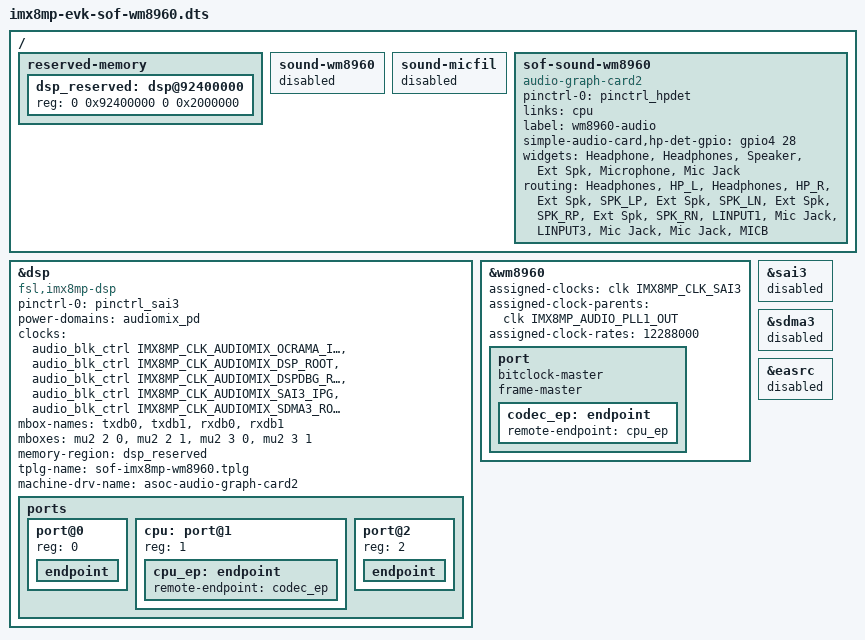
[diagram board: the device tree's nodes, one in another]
// SPDX-License-Identifier: GPL-2.0+
// Copyright NXP 2020

#include "imx8mp-evk.dts"

/delete-node/ &dsp_reserved_heap;
/delete-node/ &dsp_vdev0vring0;
/delete-node/ &dsp_vdev0vring1;
/delete-node/ &dsp_vdev0buffer;

/ {
	reserved-memory {
		dsp_reserved: dsp@92400000 {
			reg = <0 0x92400000 0 0x2000000>;
		};
	};

	sound-wm8960 {
		status = "disabled";
	};

	sound-micfil {
		status = "disabled";
	};

	sof-sound-wm8960 {
		compatible = "audio-graph-card2";
		pinctrl-names = "default";
		pinctrl-0 = <&pinctrl_hpdet>;
		links = <&cpu>;
		label = "wm8960-audio";
		simple-audio-card,hp-det-gpio = <&gpio4 28 0>;
		widgets =
			"Headphone", "Headphones",
			"Speaker", "Ext Spk",
			"Microphone", "Mic Jack";
		routing =
			"Headphones", "HP_L",
			"Headphones", "HP_R",
			"Ext Spk", "SPK_LP",
			"Ext Spk", "SPK_LN",
			"Ext Spk", "SPK_RP",
			"Ext Spk", "SPK_RN",
			"LINPUT1", "Mic Jack",
			"LINPUT3", "Mic Jack",
			"Mic Jack", "MICB";
	};

};

&dsp {
	compatible = "fsl,imx8mp-dsp";

	pinctrl-names = "default";
	pinctrl-0 = <&pinctrl_sai3>;

	power-domains = <&audiomix_pd>;

	clocks = <&audio_blk_ctrl IMX8MP_CLK_AUDIOMIX_OCRAMA_IPG>,
		<&audio_blk_ctrl IMX8MP_CLK_AUDIOMIX_DSP_ROOT>,
		<&audio_blk_ctrl IMX8MP_CLK_AUDIOMIX_DSPDBG_ROOT>,
		<&audio_blk_ctrl IMX8MP_CLK_AUDIOMIX_SAI3_IPG>,
		<&audio_blk_ctrl IMX8MP_CLK_AUDIOMIX_SDMA3_ROOT>;

	clock-names = "ipg", "ocram", "core",
		"sai3_bus", "sdma3_root";

	mbox-names = "txdb0", "txdb1", "rxdb0", "rxdb1";
	mboxes = <&mu2 2 0>, <&mu2 2 1>,
		 <&mu2 3 0>, <&mu2 3 1>;
	memory-region = <&dsp_reserved>;
	/delete-property/ firmware-name;

	tplg-name = "sof-imx8mp-wm8960.tplg";
	machine-drv-name = "asoc-audio-graph-card2";
	status = "okay";

	ports {
		#address-cells = <1>;
		#size-cells = <0>;

		port@0 { reg = <0>; endpoint { /* not used */ }; };
		cpu: port@1 { reg = <1>; cpu_ep: endpoint { remote-endpoint = <&codec_ep>; }; };
		port@2 { reg = <2>; endpoint { /* not used */ }; };
	};
};

&wm8960 {
	#sound-dai-cells = <0>;
	status = "okay";


	assigned-clocks = <&clk IMX8MP_CLK_SAI3>;
	assigned-clock-parents = <&clk IMX8MP_AUDIO_PLL1_OUT>;
	assigned-clock-rates = <12288000>;

	port {
		bitclock-master;
		frame-master;
		codec_ep: endpoint { remote-endpoint = <&cpu_ep>; };
	};

};

&sai3 {
	status = "disabled";
};

&sdma3 {
	status = "disabled";
};

&easrc {
	status = "disabled";
};
